# LPC43xx register map
File version: 10
CPU: CM4 r0p0, little endian, no MPU, no FPU, 3 interrupt priority bits
Registers are 32-bit, read-write, reset 0x0 unless marked. A register's access mark holds for its fields unless they carry their own. Offsets are from the block's base; [hi:lo] are bit positions; {n}, {i} and the like mark numbered series; 'fields as' and 'values as' point back to an identical list.

## CREG — Configuration Registers (CREG)
Base 0x40043000
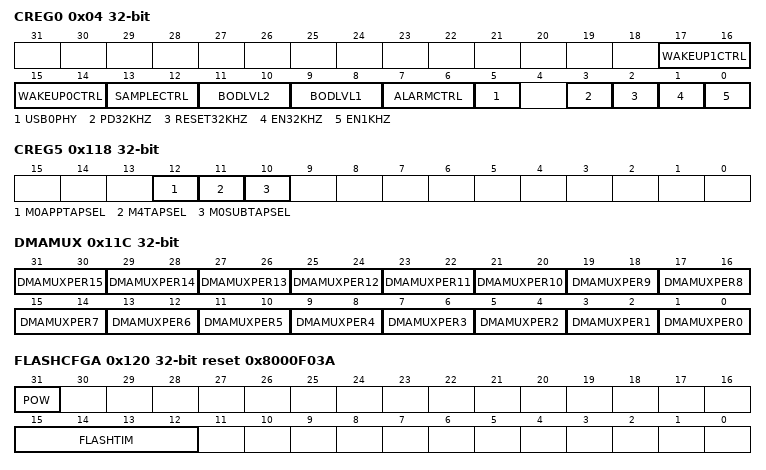
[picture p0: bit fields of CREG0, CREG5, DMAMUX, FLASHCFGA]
0x04 CREG0 reset not defined — Chip configuration register 32 kHz oscillator output and BOD control register.
  [17:16] WAKEUP1CTRL — WAKEUP1 pin input/output control
    0=INPUT_TO_EVENT_ROUTE (Input to event router.); 1=OUTPUT_FROM_THE_EVEN (Output from the event router.); 3=INPUT_TO_EVENT_ROUTE (Input to event router.)
  [15:14] WAKEUP0CTRL — WAKEUP0 pin input/output control
    0=INPUT_TO_THE_EVENT_R (Input to the event router.); 1=OUTPUT_FROM_THE_EVEN (Output from the event router.); 3=INPUT_TO_THE_EVENT_R (Input to the event router.)
  [13:12] SAMPLECTRL — SAMPLE pin input/output control
    1=SAMPLE_OUTPUT_FROM_T (Sample output from the event monitor/recorder.); 2=OUTPUT_FROM_THE_EVEN (Output from the event router.)
  [11:10] BODLVL2 — BOD trip level to generate a reset. See the LPC43xx data sheets for the trip values.
    {v}=LEVEL_{v}_RESET (v=0..3)
  [9:8] BODLVL1 — BOD trip level to generate an interrupt. See the LPC43xx data sheets for the trip values.
    {v}=LEVEL_{v}_INTERRUPT (v=0..3)
  [7:6] ALARMCTRL — RTC_ALARM pin output control
    0=RTC_ALARM; 1=EVENT_ROUTER_EVENT; 3=INACTIVE
  [5] USB0PHY — USB0 PHY power control.
    0=ENABLE_USB0_PHY_POWE (Enable USB0 PHY power.); 1=DISABLE_USB0_PHY (Disable USB0 PHY. PHY powered down.)
  [3] PD32KHZ — 32 kHz power control.
    0=POWERED; 1=POWERED_DOWN
  [2] RESET32KHZ — 32 kHz oscillator reset
    0=CLEAR_RESET; 1=RESET_ACTIVE
  [1] EN32KHZ — Enable 32 kHz output
    0=32_KHZ_OUTPUT_DISABL (32 kHz output disabled.); 1=32_KHZ_OUTPUT_ENABLE (32 kHz output enabled.)
  [0] EN1KHZ — Enable 1 kHz output.
    0=1_KHZ_OUTPUT_DISABLE (1 kHz output disabled.); 1=1_KHZ_OUTPUT_ENABLED
0x100 M4MEMMAP reset 0x10400000 — ARM Cortex-M4 memory mapping
  [31:12] M4MAP — Shadow address when accessing memory at address 0x0000 0000
0x118 CREG5 reset not defined — Chip configuration register 5. Controls JTAG access.
  [all] fields
    0=NO_EFFECT; 1=DISABLE_JTAG_DEBUG (Disable JTAG debug. Once JTAG is disabled, JTAG access remains disabled until the chip is reset by any source.)
  [12] M0APPTAPSEL — JTAG debug disable for M0APPco-processor. If this bit is set to 1, it can be changed to 0 only through a chip reset.
  [11] M4TAPSEL — JTAG debug disable for M4 main processor. If this bit is set to 1, it can be changed to 0 only through a chip reset.
  [10] M0SUBTAPSEL — JTAG debug disable for M0SUB co-processor. If this bit is set to 1, it can be changed to 0 only through a chip reset.
0x11C DMAMUX reset not defined — DMA mux control
  [31:30] DMAMUXPER15 — Select DMA to peripheral connection for DMA peripheral 15.
    0=DAC; 1=SCT_CTOUT_3; 2=SGPIO15; 3=TIMER3_MATCH_0
  [29:28] DMAMUXPER14 — Select DMA to peripheral connection for DMA peripheral 14.
    0=ADC1; 2=SSP1_TRANSMIT; 3=USART3_TRANSMIT
  [27:26] DMAMUXPER13 — Select DMA to peripheral connection for DMA peripheral 13.
    0=ADC0; 2=SSP1_RECEIVE; 3=USART3_RECEIVE
  [25:24] DMAMUXPER12 — Select DMA to peripheral connection for DMA peripheral 12.
    0=SSP1_TRANSMIT; 1=SGPIO15; 2=USART0_RECEIVE
  [23:22] DMAMUXPER11 — Selects DMA to peripheral connection for DMA peripheral 11.
    0=SSP1_RECEIVE; 1=SGPIO14; 2=USART0_TRANSMIT
  [21:20] DMAMUXPER10 — Select DMA to peripheral connection for DMA peripheral 10.
    0=SSP0_TRANSMIT; 1=I2S0_DMA_REQUEST_2; 2=SCT_DMA_REQUEST_0
  [19:18] DMAMUXPER9 — Select DMA to peripheral connection for DMA peripheral 9.
    0=SSP0_RECEIVE; 1=I2S0_DMA_REQUEST_1; 2=SCT_DMA_REQUEST_1
  [17:16] DMAMUXPER8 — Select DMA to peripheral connection for DMA peripheral 8.
    0=TIMER3_MATCH_1; 1=USART3_RECEIVE; 2=SCT_DMA_REQUEST_1; 3=ADCHS_READ
  [15:14] DMAMUXPER7 — Selects DMA to peripheral connection for DMA peripheral 7.
    0=TIMER3_MATCH_0; 1=USART3_TRANSMIT; 2=SCT_DMA_REQUEST_0; 3=ADCHS_WRITE
  [13:12] DMAMUXPER6 — Selects DMA to peripheral connection for DMA peripheral 6.
    0=TIMER2_MATCH_1; 1=USART2_RECEIVE; 2=SSP1_RECEIVE; 3=SGPIO14
  [11:10] DMAMUXPER5 — Select DMA to peripheral connection for DMA peripheral 5.
    0=TIMER2_MATCH_0; 1=USART2_TRANSMIT; 2=SSP1_TRANSMIT; 3=SGPIO15
  [9:8] DMAMUXPER4 — Select DMA to peripheral connection for DMA peripheral 4.
    0=TIMER1_MATCH_1; 1=UART1_RECEIVE; 2=I2S1_DMA_REQUEST_2; 3=SSP1_RECEIVE
  [7:6] DMAMUXPER3 — Select DMA to peripheral connection for DMA peripheral 3.
    0=TIMER1_MATCH_0; 1=UART1_TRANSMIT; 2=I2S1_DMA_REQUEST_1; 3=SSP1_TRANSMIT
  [5:4] DMAMUXPER2 — Select DMA to peripheral connection for DMA peripheral 2.
    0=TIMER0_MATCH_1; 1=USART0_RECEIVE
  [3:2] DMAMUXPER1 — Select DMA to peripheral connection for DMA peripheral 1
    0=TIMER0_MATCH_0; 1=USART0_TRANSMIT
  [1:0] DMAMUXPER0 — Select DMA to peripheral connection for DMA peripheral 0.
    0=SPIFI; 1=SCT_CTOUT_2; 2=SGPIO14; 3=TIMER3_MATCH_1
0x120 FLASHCFGA reset 0x8000F03A — Flash accelerator configuration register for flash bank A
  [31] POW — Flash bank A power control
    0=POWER_DOWN; 1=ACTIVE (Active (Default))
  [15:12] FLASHTIM — Flash access time. The value of this field plus 1 gives the number of BASE_M4_CLK clocks used for a flash access. Warning: Improper setting of this value may result in incorrect operation of the device. All other values are allowed but may not be optimal for the supported clock frequencies.
    0=1_BASE_M4_CLK_CLOCK (1 BASE_M4_CLK clock. Use for BASE_M4_CLK up to 21 MHz.); 1=2_BASE_M4_CLK_CLOCKS (2 BASE_M4_CLK clocks. Use for BASE_M4_CLK up to 43 MHz.); 2=3_BASE_M4_CLK_CLOCKS (3 BASE_M4_CLK clocks. Use for BASE_M4_CLK up to 64 MHz.); 3=4_BASE_M4_CLK_CLOCKS (4 BASE_M4_CLK clocks. Use for BASE_M4_CLK up to 86 MHz.); 4=5_BASE_M4_CLK_CLOCKS (5 BASE_M4_CLK clocks. Use for BASE_M4_CLK up to 107 MHz.); 5=6_BASE_M4_CLK_CLOCKS (6 BASE_M4_CLK clocks. Use for BASE_M4_CLK up to 129 MHz.); 6=7_BASE_M4_CLK_CLOCKS (7 BASE_M4_CLK clocks. Use for BASE_M4_CLK up to 150 MHz.); 7=8_BASE_M4_CLK_CLOCKS (8 BASE_M4_CLK clocks. Use for BASE_M4_CLK up to 172 MHz.); 8=9_BASE_M4_CLK_CLOCKS (9 BASE_M4_CLK clocks. Use for BASE_M4_CLK up to 193 MHz.); 9=10_BASE_M4_CLK_CLOCK (10 BASE_M4_CLK clocks. Use for BASE_M4_CLK up to 204 MHz. Safe setting for all allowed conditions.)
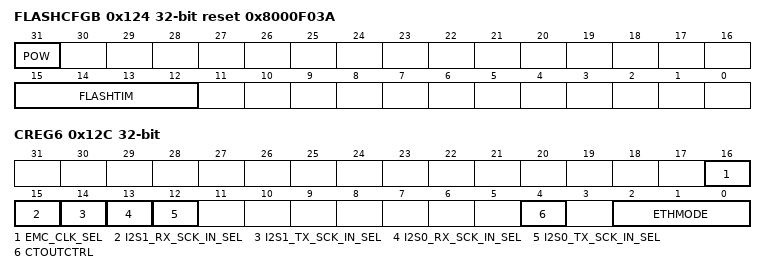
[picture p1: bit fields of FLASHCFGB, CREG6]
0x124 FLASHCFGB reset 0x8000F03A — Flash accelerator configuration register for flash bank B
  fields as FLASHCFGA
0x128 ETBCFG reset 0x1 — ETB RAM configuration
  [0] ETB — Select SRAM interface
    0=ETB_ACCESSES_SRAM_AT (ETB accesses SRAM at address 0x2000 C000.); 1=AHB_ACCESSES_SRAM_AT (AHB accesses SRAM at address 0x2000 C000.)
0x12C CREG6 — Chip configuration register 6. Controls multiple functions : Ethernet interface, SCT output, I2S0/1 inputs, EMC clock.
  [16] EMC_CLK_SEL — EMC_CLK divided clock select (see Section 21.1).
    0=DIVIDE_BY_1 (Divide by 1. EMC_CLK_DIV not divided.); 1=DIVIDE_BY_2 (Divide by 2. EMC_CLK_DIV divided by 2.)
  [15] I2S1_RX_SCK_IN_SEL — I2S1_RX_SCK input select
    0=I2S_REGISTER (I2S register. I2S clock selected as defined by the I2S receive mode register Table 961.); 1=BASE_AUDIO_CLK_FOR_I (BASE_AUDIO_CLK for I2S receive clock MCLK input and MCLK output. The I2S must be configured in slave mode.)
  [14] I2S1_TX_SCK_IN_SEL — I2S1_TX_SCK input select
    0=I2S_REGISTER (I2S register. I2S clock selected as defined by the I2S transmit mode register Table 960.); 1=BASE_AUDIO_CLK_FOR_I (BASE_AUDIO_CLK for I2S transmit clock MCLK input and MCLK output. The I2S must be configured in slave mode.)
  [13] I2S0_RX_SCK_IN_SEL — I2S0_RX_SCK input select
    0=I2S_REGISTER (I2S Register. I2S clock selected as defined by the I2S receive mode register Table 961.); 1=BASE_AUDIO_CLK_FOR_I (BASE_AUDIO_CLK for I2S receive clock MCLK input and MCLK output. The I2S must be configured in slave mode.)
  [12] I2S0_TX_SCK_IN_SEL — I2S0_TX_SCK input select
    0=I2S_REGISTER (I2S Register. I2S clock selected as defined by the I2S transmit mode register Table 960.); 1=BASE_AUDIO_CLK_FOR_I (BASE_AUDIO_CLK for I2S transmit clock MCLK input and MCLK output. The I2S must be configured in slave mode.)
  [4] CTOUTCTRL — Selects the functionality of the SCT outputs.
    0=COMBINE_SCT_AND_TIME (Combine SCT and timer match outputs. SCT outputs are Red with timer outputs.); 1=SCT_OUTPUTS_ONLY (SCT outputs only. SCT outputs are used without timer match outputs.)
  [2:0] ETHMODE — Selects the Ethernet mode. Reset the ethernet after changing the PHY interface. All other settings are reserved.
    0=MII; 4=RMII
0x130 M4TXEVENT — Cortex-M4 TXEV event clear
  [0] TXEVCLR — Cortex-M4 TXEV event.
    0=CLEAR_THE_TXEV_EVENT; 1=NO_EFFECT
0x200 CHIPID ro reset not defined — Part ID
  [31:0] ID — Boundary scan ID code 0x5906 002B or 0x6906 002B = LPC4350/30/20/10 (flashless parts) 0x4906 002B = LPC4357/53 (parts with on-chip flash)
0x308 M0SUBMEMMAP reset 0x18400000 — ARM Cortex-M0SUB memory mapping
  [31:12] M0SUBMAP — Shadow address when accessing memory at address 0x0000 0000
0x314 M0SUBTXEVENT — Cortex-M0SUB TXEV event clear
  [0] TXEVCLR — Cortex-M0SUB TXEV event handling.
    0=CLEAR_THE_TXEV_EVENT; 1=NO_EFFECT
0x400 M0APPTXEVENT — Cortex-M0APP TXEV event clear
  [0] TXEVCLR — Cortex-M0APP TXEV event handling.
    0=CLEAR_THE_TXEV_EVENT; 1=NO_EFFECT
0x404 M0APPMEMMAP reset 0x20000000 — ARM Cortex-M0APP memory mapping
  [31:12] M0APPMAP — Shadow address when accessing memory at address 0x0000 0000
0x500 USB0FLADJ reset 0x20 — USB0 frame length adjust register
  [5:0] FLTV — Frame length timing value The frame length is given in the number of high-speed bit times in decimal format. Each decimal value change to this register corresponds to 16 high-speed bit times. The SOF cycle time (number of SOF counter clock periods to generate a SOF micro-frame length) is equal to 59488 + value in this field. The default value is decimal 32 (0x20), which results in a SOF cycle time of 60000. 0x00 = 59488 (= 59488 + 0 x 16) 0x01 = 59504 (= 59488 + 1 x 16) 0x02 = 59520 (= 59488 + 2 x 16) ... 0x1F = 59984 (= 59488 + 31 x 16) 0x20 = 60000 (= 59488 + 32 x 16) ... 0x3E = 60480 (= 59488 + 62 x 16) 0x3F = 60496 (= 59488 + 63 x 16)
0x600 USB1FLADJ reset 0x20 — USB1 frame length adjust register
  fields as USB0FLADJ
